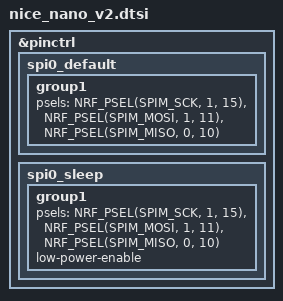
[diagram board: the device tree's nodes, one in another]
&pinctrl {
    /* configuration for spi0 device, default state */
    spi0_default: spi0_default {
        /* node name is arbitrary */
        group1 {
            /* main role: configure P0.01 as SPI clock, P0.02 as SPI MOSI, P0.03 as SPI MISO */
            psels = <NRF_PSEL(SPIM_SCK, 1, 15)>,
                    <NRF_PSEL(SPIM_MOSI, 1, 11)>,
                    <NRF_PSEL(SPIM_MISO, 0, 10)>;
        };
    };

    /* configuration for spi0 device, sleep state */
    spi0_sleep: spi0_sleep {
        group1 {
            /* main role: configure P0.01 as SPI clock, P0.02 as SPI MOSI, P0.03 as SPI MISO */
            psels = <NRF_PSEL(SPIM_SCK, 1, 15)>,
                    <NRF_PSEL(SPIM_MOSI, 1, 11)>,
                    <NRF_PSEL(SPIM_MISO, 0, 10)>;
            low-power-enable;
        };
    };

};
